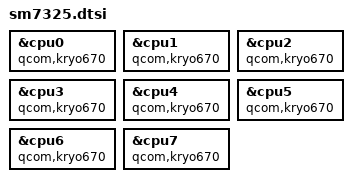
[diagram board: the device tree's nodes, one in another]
// SPDX-License-Identifier: BSD-3-Clause
/*
 * Copyright (c) 2024, Eugene Lepshy <fekz115@gmail.com>
 * Copyright (c) 2024, Danila Tikhonov <danila@jiaxyga.com>
 */

#include "sc7280.dtsi"

/* SM7325 uses Kryo 670 */
&cpu0 { compatible = "qcom,kryo670"; };
&cpu1 { compatible = "qcom,kryo670"; };
&cpu2 { compatible = "qcom,kryo670"; };
&cpu3 { compatible = "qcom,kryo670"; };
&cpu4 { compatible = "qcom,kryo670"; };
&cpu5 { compatible = "qcom,kryo670"; };
&cpu6 { compatible = "qcom,kryo670"; };
&cpu7 { compatible = "qcom,kryo670"; };
